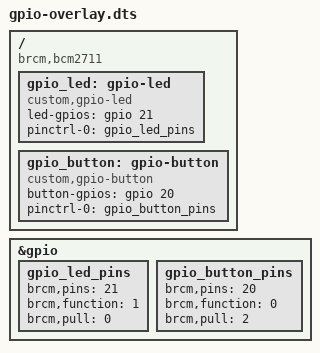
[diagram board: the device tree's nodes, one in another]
/dts-v1/;
/plugin/;

/ {
    compatible = "brcm,bcm2711";

    fragment@0 {
        target-path = "/";
        __overlay__ {
            gpio_led: gpio-led {
                compatible = "custom,gpio-led";
                status = "okay";

                led-gpios = <&gpio 21 0>;     // GPIO21, active high (LED)

                pinctrl-names = "default";
                pinctrl-0 = <&gpio_led_pins>;
            };
        };
    };

    fragment@1 {
        target-path = "/";
        __overlay__ {
            gpio_button: gpio-button {
                compatible = "custom,gpio-button";
                status = "okay";

                button-gpios = <&gpio 20 0>;  // GPIO20, active high (Button)

                pinctrl-names = "default";
                pinctrl-0 = <&gpio_button_pins>;
            };
        };
    };

    fragment@2 {
        target = <&gpio>;
        __overlay__ {
            gpio_led_pins: gpio_led_pins {
                brcm,pins = <21>;
                brcm,function = <1>;    // GPIO21=output (LED)
                brcm,pull = <0>;        // GPIO21=no pull
            };

            gpio_button_pins: gpio_button_pins {
                brcm,pins = <20>;
                brcm,function = <0>;    // GPIO20=input (button)
                brcm,pull = <2>;        // GPIO20=pull-up
            };
        };
    };
};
